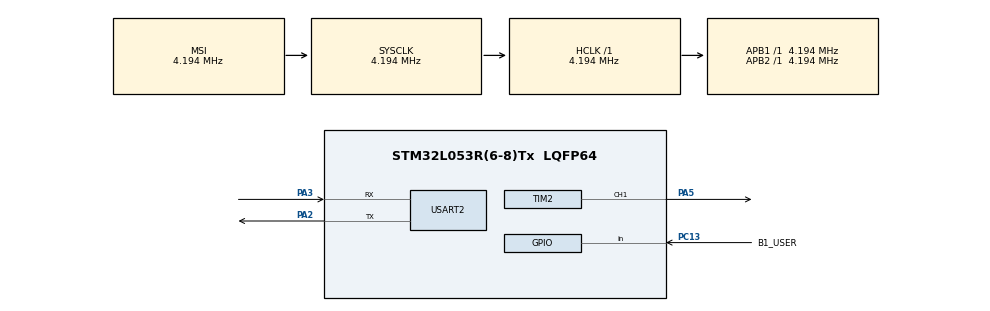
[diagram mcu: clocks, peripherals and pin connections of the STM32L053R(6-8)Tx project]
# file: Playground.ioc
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Dma.Request0=USART2_RX
Dma.Request1=USART2_TX
Dma.USART2_RX.0.Direction=DMA_PERIPH_TO_MEMORY
Dma.USART2_RX.0.Instance=DMA1_Channel5
Dma.USART2_RX.0.MemDataAlignment=DMA_MDATAALIGN_BYTE
Dma.USART2_RX.0.MemInc=DMA_MINC_ENABLE
Dma.USART2_RX.0.Mode=DMA_NORMAL
Dma.USART2_RX.0.PeriphDataAlignment=DMA_PDATAALIGN_BYTE
Dma.USART2_RX.0.PeriphInc=DMA_PINC_DISABLE
Dma.USART2_RX.0.Priority=DMA_PRIORITY_LOW
Dma.USART2_TX.1.Direction=DMA_MEMORY_TO_PERIPH
Dma.USART2_TX.1.Instance=DMA1_Channel4
Dma.USART2_TX.1.MemDataAlignment=DMA_MDATAALIGN_BYTE
Dma.USART2_TX.1.MemInc=DMA_MINC_ENABLE
Dma.USART2_TX.1.Mode=DMA_NORMAL
Dma.USART2_TX.1.PeriphDataAlignment=DMA_PDATAALIGN_BYTE
Dma.USART2_TX.1.PeriphInc=DMA_PINC_DISABLE
Dma.USART2_TX.1.Priority=DMA_PRIORITY_LOW
Mcu.Family=STM32L0
Mcu.Name=STM32L053R(6-8)Tx
Mcu.Package=LQFP64
NVIC.DMA1_Channel4_5_6_7_IRQn=true\:0\:0\:false\:false\:true\:false\:true\:true
NVIC.TIM21_IRQn=true\:0\:0\:false\:false\:true\:true\:true\:true
NVIC.USART2_IRQn=true\:0\:0\:false\:false\:true\:true\:true\:true
PA2.Mode=Asynchronous
PA2.Signal=USART2_TX
PA3.Mode=Asynchronous
PA3.Signal=USART2_RX
PA5.Signal=S_TIM2_CH1
PC13.GPIO_Label=B1_USER
PC13.Signal=GPIO_Input
ProjectManager.HeapSize=0x200
ProjectManager.StackSize=0x400
ProjectManager.TargetToolchain=STM32CubeIDE
RCC.AHBFreq_Value=4194000
RCC.APB1Freq_Value=4194000
RCC.APB1TimFreq_Value=4194000
RCC.APB2Freq_Value=4194000
RCC.APB2TimFreq_Value=4194000
RCC.HCLKFreq_Value=4194000
RCC.HSE_VALUE=8000000
RCC.HSI16_VALUE=16000000
RCC.HSI48_VALUE=48000000
RCC.HSI_VALUE=16000000
RCC.LSE_VALUE=32768
RCC.MSIClockRange=RCC_MSIRANGE_6
RCC.MSI_VALUE=4194000
RCC.SYSCLKFreq_VALUE=4194000
RCC.VCOOutputFreq_Value=48000000
SH.S_TIM2_CH1.0=TIM2_CH1,PWM Generation1 CH1
TIM2.Channel-PWM\ Generation1\ CH1=TIM_CHANNEL_1
TIM2.Period=4193
TIM2.Prescaler=0
TIM21.Period=41939
TIM21.Prescaler=0
USART2.VirtualMode-Asynchronous=VM_ASYNC
VP_TIM21_VS_ClockSourceINT.Mode=Internal
VP_TIM2_VS_ClockSourceINT.Mode=Internal
board=custom

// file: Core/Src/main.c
/* USER CODE BEGIN Header */
/**
  ******************************************************************************
  * @file           : main.c
  * @brief          : Main program body
  ******************************************************************************
  * @attention
  *
  * Copyright (c) 2024 STMicroelectronics.
  * All rights reserved.
  *
  * This software is licensed under terms that can be found in the LICENSE file
  * in the root directory of this software component.
  * If no LICENSE file comes with this software, it is provided AS-IS.
  *
  ******************************************************************************
  */
/* USER CODE END Header */
#include "main.h"

/* USER CODE BEGIN Includes */
#include "Service/TimBase.h"
#include "Service/Led.h"
#include "Service/Uart.h"
#include "Task/TaskMain.h"

/* USER CODE END Includes */

TIM_HandleTypeDef htim2;
TIM_HandleTypeDef htim21;

UART_HandleTypeDef huart2;
DMA_HandleTypeDef hdma_usart2_rx;
DMA_HandleTypeDef hdma_usart2_tx;

void SystemClock_Config(void);
static void MX_GPIO_Init(void);
static void MX_DMA_Init(void);
static void MX_TIM2_Init(void);
static void MX_TIM21_Init(void);
static void MX_USART2_UART_Init(void);

int main(void)
{

  /* MCU Configuration--------------------------------------------------------*/

  /* Reset of all peripherals, Initializes the Flash interface and the Systick. */
  HAL_Init();

  /* Configure the system clock */
  SystemClock_Config();

  /* Initialize all configured peripherals */
  MX_GPIO_Init();
  MX_DMA_Init();
  MX_TIM2_Init();
  MX_TIM21_Init();
  MX_USART2_UART_Init();
  /* USER CODE BEGIN 2 */
  vidTimBaseInitialize();
  vidSrvLedInitialize();
  vidSrvUartInitialize();
  vidTaskMainInitialize();

  /* USER CODE END 2 */

  /* Infinite loop */
  while (1)
  {

    /* USER CODE BEGIN 3 */
    vidTaskMainProcess();
  }
  /* USER CODE END 3 */
}

void SystemClock_Config(void)
{
  RCC_OscInitTypeDef RCC_OscInitStruct = {0};
  RCC_ClkInitTypeDef RCC_ClkInitStruct = {0};
  RCC_PeriphCLKInitTypeDef PeriphClkInit = {0};

  /** Configure the main internal regulator output voltage
  */
  __HAL_PWR_VOLTAGESCALING_CONFIG(PWR_REGULATOR_VOLTAGE_SCALE1);

  /** Initializes the RCC Oscillators according to the specified parameters
  * in the RCC_OscInitTypeDef structure.
  */
  RCC_OscInitStruct.OscillatorType = RCC_OSCILLATORTYPE_MSI;
  RCC_OscInitStruct.MSIState = RCC_MSI_ON;
  RCC_OscInitStruct.MSICalibrationValue = 0;
  RCC_OscInitStruct.MSIClockRange = RCC_MSIRANGE_6;
  RCC_OscInitStruct.PLL.PLLState = RCC_PLL_NONE;
  if (HAL_RCC_OscConfig(&RCC_OscInitStruct) != HAL_OK)
  {
    Error_Handler();
  }

  /** Initializes the CPU, AHB and APB buses clocks
  */
  RCC_ClkInitStruct.ClockType = RCC_CLOCKTYPE_HCLK|RCC_CLOCKTYPE_SYSCLK
                              |RCC_CLOCKTYPE_PCLK1|RCC_CLOCKTYPE_PCLK2;
  RCC_ClkInitStruct.SYSCLKSource = RCC_SYSCLKSOURCE_MSI;
  RCC_ClkInitStruct.AHBCLKDivider = RCC_SYSCLK_DIV1;
  RCC_ClkInitStruct.APB1CLKDivider = RCC_HCLK_DIV1;
  RCC_ClkInitStruct.APB2CLKDivider = RCC_HCLK_DIV1;

  if (HAL_RCC_ClockConfig(&RCC_ClkInitStruct, FLASH_LATENCY_0) != HAL_OK)
  {
    Error_Handler();
  }
  PeriphClkInit.PeriphClockSelection = RCC_PERIPHCLK_USART2;
  PeriphClkInit.Usart2ClockSelection = RCC_USART2CLKSOURCE_PCLK1;
  if (HAL_RCCEx_PeriphCLKConfig(&PeriphClkInit) != HAL_OK)
  {
    Error_Handler();
  }
}

static void MX_TIM2_Init(void)
{

  TIM_ClockConfigTypeDef sClockSourceConfig = {0};
  TIM_MasterConfigTypeDef sMasterConfig = {0};
  TIM_OC_InitTypeDef sConfigOC = {0};

  htim2.Instance = TIM2;
  htim2.Init.Prescaler = 0;
  htim2.Init.CounterMode = TIM_COUNTERMODE_UP;
  htim2.Init.Period = 4193;
  htim2.Init.ClockDivision = TIM_CLOCKDIVISION_DIV1;
  htim2.Init.AutoReloadPreload = TIM_AUTORELOAD_PRELOAD_DISABLE;
  if (HAL_TIM_Base_Init(&htim2) != HAL_OK)
  {
    Error_Handler();
  }
  sClockSourceConfig.ClockSource = TIM_CLOCKSOURCE_INTERNAL;
  if (HAL_TIM_ConfigClockSource(&htim2, &sClockSourceConfig) != HAL_OK)
  {
    Error_Handler();
  }
  if (HAL_TIM_PWM_Init(&htim2) != HAL_OK)
  {
    Error_Handler();
  }
  sMasterConfig.MasterOutputTrigger = TIM_TRGO_RESET;
  sMasterConfig.MasterSlaveMode = TIM_MASTERSLAVEMODE_DISABLE;
  if (HAL_TIMEx_MasterConfigSynchronization(&htim2, &sMasterConfig) != HAL_OK)
  {
    Error_Handler();
  }
  sConfigOC.OCMode = TIM_OCMODE_PWM1;
  sConfigOC.Pulse = 0;
  sConfigOC.OCPolarity = TIM_OCPOLARITY_HIGH;
  sConfigOC.OCFastMode = TIM_OCFAST_DISABLE;
  if (HAL_TIM_PWM_ConfigChannel(&htim2, &sConfigOC, TIM_CHANNEL_1) != HAL_OK)
  {
    Error_Handler();
  }
  HAL_TIM_MspPostInit(&htim2);

}

static void MX_TIM21_Init(void)
{

  TIM_ClockConfigTypeDef sClockSourceConfig = {0};
  TIM_MasterConfigTypeDef sMasterConfig = {0};

  htim21.Instance = TIM21;
  htim21.Init.Prescaler = 0;
  htim21.Init.CounterMode = TIM_COUNTERMODE_UP;
  htim21.Init.Period = 41939;
  htim21.Init.ClockDivision = TIM_CLOCKDIVISION_DIV1;
  htim21.Init.AutoReloadPreload = TIM_AUTORELOAD_PRELOAD_DISABLE;
  if (HAL_TIM_Base_Init(&htim21) != HAL_OK)
  {
    Error_Handler();
  }
  sClockSourceConfig.ClockSource = TIM_CLOCKSOURCE_INTERNAL;
  if (HAL_TIM_ConfigClockSource(&htim21, &sClockSourceConfig) != HAL_OK)
  {
    Error_Handler();
  }
  sMasterConfig.MasterOutputTrigger = TIM_TRGO_RESET;
  sMasterConfig.MasterSlaveMode = TIM_MASTERSLAVEMODE_DISABLE;
  if (HAL_TIMEx_MasterConfigSynchronization(&htim21, &sMasterConfig) != HAL_OK)
  {
    Error_Handler();
  }

}

static void MX_USART2_UART_Init(void)
{

  huart2.Instance = USART2;
  huart2.Init.BaudRate = 115200;
  huart2.Init.WordLength = UART_WORDLENGTH_8B;
  huart2.Init.StopBits = UART_STOPBITS_1;
  huart2.Init.Parity = UART_PARITY_NONE;
  huart2.Init.Mode = UART_MODE_TX_RX;
  huart2.Init.HwFlowCtl = UART_HWCONTROL_NONE;
  huart2.Init.OverSampling = UART_OVERSAMPLING_16;
  huart2.Init.OneBitSampling = UART_ONE_BIT_SAMPLE_DISABLE;
  huart2.AdvancedInit.AdvFeatureInit = UART_ADVFEATURE_NO_INIT;
  if (HAL_UART_Init(&huart2) != HAL_OK)
  {
    Error_Handler();
  }

}

static void MX_DMA_Init(void)
{

  /* DMA controller clock enable */
  __HAL_RCC_DMA1_CLK_ENABLE();

  /* DMA interrupt init */
  /* DMA1_Channel4_5_6_7_IRQn interrupt configuration */
  HAL_NVIC_SetPriority(DMA1_Channel4_5_6_7_IRQn, 0, 0);
  HAL_NVIC_EnableIRQ(DMA1_Channel4_5_6_7_IRQn);

}

static void MX_GPIO_Init(void)
{
  GPIO_InitTypeDef GPIO_InitStruct = {0};

  /* GPIO Ports Clock Enable */
  __HAL_RCC_GPIOC_CLK_ENABLE();
  __HAL_RCC_GPIOA_CLK_ENABLE();

  /*Configure GPIO pin : B1_USER_Pin */
  GPIO_InitStruct.Pin = B1_USER_Pin;
  GPIO_InitStruct.Mode = GPIO_MODE_INPUT;
  GPIO_InitStruct.Pull = GPIO_NOPULL;
  HAL_GPIO_Init(B1_USER_GPIO_Port, &GPIO_InitStruct);

}

void Error_Handler(void)
{
  __disable_irq();
  while (1)
  {
  }
}
